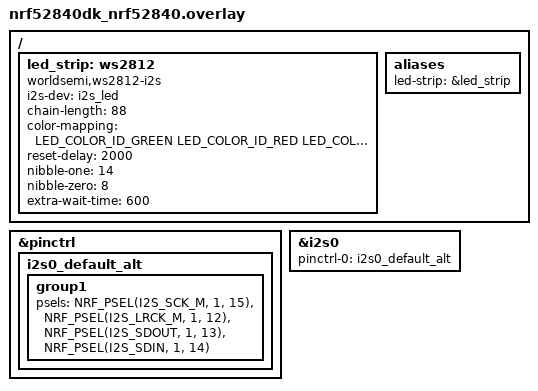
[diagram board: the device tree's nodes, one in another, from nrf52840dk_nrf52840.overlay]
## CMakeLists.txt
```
# SPDX-License-Identifier: Apache-2.0

cmake_minimum_required(VERSION 3.20.0)
find_package(Zephyr REQUIRED HINTS $ENV{ZEPHYR_BASE})
project(observer)

target_sources(app PRIVATE
  src/main.c
  src/observer.c
)
```

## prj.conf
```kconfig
# Button and LED library
CONFIG_DK_LIBRARY=y

#Bluetooth
CONFIG_BT=y
CONFIG_BT_OBSERVER=y

CONFIG_BT_CTLR_RX_BUFFERS=9

# Increase stack size for the main thread and System Workqueue
CONFIG_SYSTEM_WORKQUEUE_STACK_SIZE=2048
CONFIG_MAIN_STACK_SIZE=2048

# WS2812B led strip
CONFIG_SPI=y
CONFIG_LED_STRIP=y
CONFIG_WS2812_STRIP=y
CONFIG_I2S=y
CONFIG_WS2812_STRIP_I2S=y
```

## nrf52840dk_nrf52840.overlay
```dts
// To get started, press Ctrl+Space to bring up the completion menu and view the available nodes.

// You can also use the buttons in the sidebar to perform actions on nodes.
// Actions currently available include:

// * Enabling / disabling the node
// * Adding the bus to a bus
// * Removing the node
// * Connecting ADC channels

// For more help, browse the DeviceTree documentation at https://docs.zephyrproject.org/latest/guides/dts/index.html
// You can also visit the nRF DeviceTree extension documentation at https://nrfconnect.github.io/vscode-nrf-connect/devicetree/nrfdevicetree.html
#include <zephyr/dt-bindings/led/led.h>
#include "nrf52-bindings.h"

&pinctrl {
	i2s0_default_alt: i2s0_default_alt {
		group1 {
			psels = <NRF_PSEL(I2S_SCK_M, 1, 15)>,
				<NRF_PSEL(I2S_LRCK_M, 1, 12)>,
				<NRF_PSEL(I2S_SDOUT, 1, 13)>, // Output pin to LED strip
				<NRF_PSEL(I2S_SDIN, 1, 14)>;
		};
	};
};

i2s_led: &i2s0 {
	status = "okay";
	pinctrl-0 = <&i2s0_default_alt>;
	pinctrl-names = "default";
};

/ {
	//compatible = "nordic,nrf7002-dk-nrf5340-cpuapp";
	led_strip: ws2812 {
		compatible = "worldsemi,ws2812-i2s";

		i2s-dev = < &i2s_led >;
		chain-length = <88>;
		color-mapping = <LED_COLOR_ID_GREEN
					LED_COLOR_ID_RED
					LED_COLOR_ID_BLUE>;
		reset-delay = <2000>; // not sure if increasing this helped
		nibble-one = < 14 >; // default value
		nibble-zero = < 8 >; // default value
		extra-wait-time = < 600 >; // this did not help
		
	};

	aliases {
		led-strip = &led_strip;
	};
};
```

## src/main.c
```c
/*
 * Copyright (c) 2022 Nordic Semiconductor ASA
 *
 * SPDX-License-Identifier: Apache-2.0
 */

#include <zephyr/kernel.h>
#include <zephyr/sys/printk.h>
#include <zephyr/bluetooth/bluetooth.h>
#include <dk_buttons_and_leds.h>
#include <stdio.h>
#include <string.h>
#include <math.h>
#include <zephyr/drivers/led_strip.h>
#include <zephyr/device.h>
#include <zephyr/drivers/i2s.h>
#include <zephyr/sys/util.h>

/* RTOS Task properties */
#define SB_STACKSIZE       1024
#define SB_PRIORITY        5 

#define TEAM_HOME_SERVING_BIT           1  // 1
#define TEAM_GUEST_SERVING_BIT          2  // 2

#define NAME_LEN 30
#define MAN_LEN  8
#define BT_DEVICE "Score Board"

#define STRIP_NODE		DT_ALIAS(led_strip)
#define STRIP_NUM_PIXELS	DT_PROP(DT_ALIAS(led_strip), chain_length)

#define RGB_LEDS_PER_DIGIT 14

#define RGB(_r, _g, _b) { .r = (_r), .g = (_g), .b = (_b) }

static const struct led_rgb colors[] = {
	RGB(0xFF, 0x00, 0x00), /* red */
	RGB(0x00, 0xFF, 0x00), /* green */
	RGB(0x00, 0x00, 0xFF), /* blue */
};

static const struct led_rgb black = {
	.r = 0x00,
	.g = 0x00,
	.b = 0x00,
};

struct led_rgb pixels[STRIP_NUM_PIXELS];

static const struct device *const strip = DEVICE_DT_GET(STRIP_NODE);

/* Define semaphore */
K_SEM_DEFINE(sem, 0, 1);

char bt_device_name[NAME_LEN] = {0,};
bool bt_device_found = false;
uint8_t bt_man_data[MAN_LEN] = {0,};
uint8_t bt_man_data_curr[MAN_LEN] = {0,};

long numbers[] = {
  0b00111111111111,  // [0] 0
  0b00110000000011,  // [1] 1
  0b11111100111100,  // [2] 2
  0b11111100001111,  // [3] 3
  0b11110011000011,  // [4] 4
  0b11001111001111,  // [5] 5
  0b11001111111111,  // [6] 6
  0b00111100000011,  // [7] 7
  0b11111111111111,  // [8] 8
  0b11111111000011,  // [9] 9
 };


void update_points(uint8_t homepoints, uint8_t guestpoints)
{
	uint8_t guest_digit_zero_index = 0;
	uint8_t guest_digit_one_index = 14;
	uint8_t home_digit_zero_index = 28;
	uint8_t home_digit_one_index = 42;
	uint8_t d1 = guestpoints / 10;  
	uint8_t d0 = guestpoints % 10; 
	uint8_t d3 = homepoints / 10; 
	uint8_t d2 = homepoints % 10;  
	uint8_t i = 0;

	for(i = 0; i < RGB_LEDS_PER_DIGIT; i++)
	{
		if((numbers[d0] & 1 << i) == 1 << i)
		{
	  		memcpy(&pixels[i + guest_digit_zero_index], &colors[0], sizeof(struct led_rgb));
        }
        else
        {
	  		memcpy(&pixels[i + guest_digit_zero_index], &black, sizeof(struct led_rgb));	
		}
	}

	for(i = 0; i < RGB_LEDS_PER_DIGIT; i++)
	{
		if((numbers[d1] & 1 << i) == 1 << i)
		{
			memcpy(&pixels[i + guest_digit_one_index], &colors[0], sizeof(struct led_rgb));
		}
		else
		{
			memcpy(&pixels[i + guest_digit_one_index], &black, sizeof(struct led_rgb));
		}
	}	

	for(i = 0; i < RGB_LEDS_PER_DIGIT; i++)
	{
		if((numbers[d2] & 1 << i) == 1 << i)
		{
	  		memcpy(&pixels[i + home_digit_zero_index], &colors[0], sizeof(struct led_rgb));
        }
        else
        {
	  		memcpy(&pixels[i + home_digit_zero_index], &black, sizeof(struct led_rgb));	
		}
	}

	for(i = 0; i < RGB_LEDS_PER_DIGIT; i++)
	{
		if((numbers[d3] & 1 << i) == 1 << i)
		{
			memcpy(&pixels[i + home_digit_one_index], &colors[0], sizeof(struct led_rgb));
		}
		else
		{
			memcpy(&pixels[i + home_digit_one_index], &black, sizeof(struct led_rgb));
		}
	}

	led_strip_update_rgb(strip, pixels, STRIP_NUM_PIXELS);
}

void update_serving(uint8_t serving)
{
	if((serving & TEAM_HOME_SERVING_BIT) == TEAM_HOME_SERVING_BIT)
	{
		memcpy(&pixels[56], &colors[0], sizeof(struct led_rgb));		
		memcpy(&pixels[57], &colors[0], sizeof(struct led_rgb));		
		memcpy(&pixels[58], &black, sizeof(struct led_rgb));		
		memcpy(&pixels[59], &black, sizeof(struct led_rgb));		
	}
	else if((serving & TEAM_GUEST_SERVING_BIT) == TEAM_GUEST_SERVING_BIT)
	{
		memcpy(&pixels[56], &black, sizeof(struct led_rgb));		
		memcpy(&pixels[57], &black, sizeof(struct led_rgb));		
		memcpy(&pixels[58], &colors[0], sizeof(struct led_rgb));		
		memcpy(&pixels[59], &colors[0], sizeof(struct led_rgb));		
	}
	else if(serving == 0)
	{
		memcpy(&pixels[56], &black, sizeof(struct led_rgb));		
		memcpy(&pixels[57], &black, sizeof(struct led_rgb));		
		memcpy(&pixels[58], &black, sizeof(struct led_rgb));		
		memcpy(&pixels[59], &black, sizeof(struct led_rgb));		
	}

	led_strip_update_rgb(strip, pixels, STRIP_NUM_PIXELS);
}

void update_sets(uint8_t homesets, uint8_t guestsets)
{
	uint8_t guest_digit_index = 60;
	uint8_t home_digit_index = 74;
	uint8_t i = 0;

	for(i = 0; i < RGB_LEDS_PER_DIGIT; i++)
	{
		if((numbers[guestsets] & 1 << i) == 1 << i)
		{
	  		memcpy(&pixels[i + guest_digit_index], &colors[0], sizeof(struct led_rgb));
        }
        else
        {
	  		memcpy(&pixels[i + guest_digit_index], &black, sizeof(struct led_rgb));	
		}
	}

	for(i = 0; i < RGB_LEDS_PER_DIGIT; i++)
	{
		if((numbers[homesets] & 1 << i) == 1 << i)
		{
	  		memcpy(&pixels[i + home_digit_index], &colors[0], sizeof(struct led_rgb));
        }
        else
        {
	  		memcpy(&pixels[i + home_digit_index], &black, sizeof(struct led_rgb));	
		}
	}

	led_strip_update_rgb(strip, pixels, STRIP_NUM_PIXELS);
}

static bool data_cb(struct bt_data *data, void *user_data)
{
	uint8_t len;
	int cmp, res = 0;

	switch (data->type) 
	{
		case BT_DATA_NAME_SHORTENED:
		case BT_DATA_NAME_COMPLETE:
			len = MIN(data->data_len, NAME_LEN - 1);
			(void)memcpy(bt_device_name, data->data, len);
			res = memcmp(bt_device_name, BT_DEVICE, 11);
			bt_device_name[len] = '\0';
			if(res == 0)
			{
				bt_device_found = true;				
				return true;				
			}
			else
			{
				return false;
			}

		case BT_DATA_MANUFACTURER_DATA:

			if(bt_device_found == true)
			{
				bt_device_found = false;
				(void)memcpy(bt_man_data, data->data, data->data_len);
				cmp = memcmp(bt_man_data_curr, bt_man_data, MAN_LEN);
				if(cmp != 0)
				{
					k_sem_give(&sem);
				}
				
			}
			return false;	

		default:
			return true;
	}
}


static void device_found(const bt_addr_le_t *addr, int8_t rssi, uint8_t type,
			 struct net_buf_simple *ad)
{
	bt_data_parse(ad, data_cb, NULL);	
}


int thread0(void)
{
	int err;
	
	struct bt_le_scan_param scan_param = {
		.type       = BT_LE_SCAN_TYPE_ACTIVE,
		.options    = BT_LE_SCAN_OPT_FILTER_DUPLICATE,
		.interval   = BT_GAP_SCAN_FAST_INTERVAL,
		.window     = BT_GAP_SCAN_FAST_WINDOW,
	};

	printk("Starting Observer Demo\n");

	/* Initialize the Bluetooth Subsystem */
	err = bt_enable(NULL);
	if (err) {
		printk("Bluetooth init failed (err %d)\n", err);
		return 0;
	}

	err = bt_le_scan_start(&scan_param, device_found);
	if (err) {
		printk("Start scanning failed (err %d)\n", err);
		return err;
	}

	if (device_is_ready(strip)) {
		printk("Found LED strip device %s", strip->name);
	} else {
		printk("LED strip device %s is not ready", strip->name);
		return 0;
	}

	memset(&pixels, 0x00, sizeof(pixels));
	led_strip_update_rgb(strip, pixels, STRIP_NUM_PIXELS);

	update_points(0, 0);
	update_serving(0);
	update_sets(0, 0);	

	printk("Started scanning...\n");
	
	while(1)
	{		
		k_sem_take(&sem, K_FOREVER);

		printk("Device Name: %s ", bt_device_name);
		printk("\n");

		printk("Manufacturer data: ");
		for (uint16_t i=0; i<MAN_LEN; i++)
		{
			printk("%02x:", bt_man_data[i]);
		}
		printk("\n");

		update_points(bt_man_data[2], bt_man_data[3]);		
		update_sets(bt_man_data[4], bt_man_data[5]);
		update_serving(bt_man_data[6]);	

		memcpy(bt_man_data_curr, bt_man_data, MAN_LEN);
	}	
}

K_THREAD_DEFINE(thread0id, SB_STACKSIZE, thread0, NULL, NULL, NULL,
				SB_PRIORITY, 0, 0);
```

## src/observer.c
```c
/*
 * Copyright (c) 2022 Nordic Semiconductor ASA
 * Copyright (c) 2015-2016 Intel Corporation
 *
 * SPDX-License-Identifier: Apache-2.0
 */

#include <zephyr/sys/printk.h>
#include <zephyr/bluetooth/bluetooth.h>
#include <zephyr/bluetooth/hci.h>
#include <stdio.h>
#include <string.h>

#define NAME_LEN 30
#define BT_DEVICE "Score Board"

static bool data_cb(struct bt_data *data, void *user_data)
{
	char *name = user_data;
	uint8_t len;
	int res = 0;

	switch (data->type) {
	case BT_DATA_NAME_SHORTENED:
	case BT_DATA_NAME_COMPLETE:
		len = MIN(data->data_len, NAME_LEN - 1);
		(void)memcpy(name, data->data, len);
		res = memcmp(name, BT_DEVICE, 11);
		if(res == 0)
		{
			name[len] = '\0';
			printk("Device Name: %s ", name);
			printk("\n");
			return true;				
		}
		else
		{
			return false;
		}

	case BT_DATA_MANUFACTURER_DATA:
		printk("Manufacturer data: ");
		for (uint16_t i=0; i<data->data_len; i++)
		{
			printk("%02x:", data->data[i]);
		}
		printk("\n");
    	return false;

	default:
		return true;
	}
}


static void device_found(const bt_addr_le_t *addr, int8_t rssi, uint8_t type,
			 struct net_buf_simple *ad)
{
	char name[NAME_LEN];

	bt_data_parse(ad, data_cb, name);
	//printk("scan_recv: %s\n", name);
}


int observer_start(void)
{
	int err;
	
	struct bt_le_scan_param scan_param = {
		.type       = BT_LE_SCAN_TYPE_ACTIVE,
		.options    = BT_LE_SCAN_OPT_FILTER_DUPLICATE,
		.interval   = BT_GAP_SCAN_FAST_INTERVAL,
		.window     = BT_GAP_SCAN_FAST_WINDOW,
	};

	err = bt_le_scan_start(&scan_param, device_found);
	if (err) {
		printk("Start scanning failed (err %d)\n", err);
		return err;
	}
	printk("Started scanning...\n");

	return 0;
}
```
